# STM32U385xx register map
File version: 1.0
Registers are 32-bit, read-write, reset 0x0 unless marked. A register's access mark holds for its fields unless they carry their own. Offsets are from the block's base; [hi:lo] are bit positions; lines under a group give offsets from that group; {n}, {i} and the like mark numbered series; 'fields as' and 'values as' point back to an identical list.

## TSC — Touch Sensing Controller (TSC)
Base 0x40024000
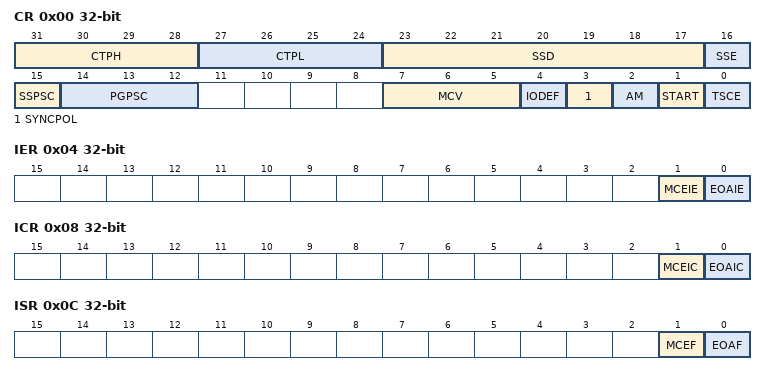
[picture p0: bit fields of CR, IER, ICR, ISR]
0x00 CR — TSC control register
  [31:28] CTPH — CTPH[3:0] bits (Charge Transfer pulse high)
  [27:24] CTPL — CTPL[3:0] bits (Charge Transfer pulse low)
  [23:17] SSD — SSD[6:0] bits (Spread Spectrum Deviation)
  [16] SSE — Spread Spectrum Enable
  [15] SSPSC — Spread Spectrum Prescaler
  [14:12] PGPSC — PGPSC[2:0] bits (Pulse Generator Prescaler)
  [7:5] MCV — MCV[2:0] bits (Max Count Value)
  [4] IODEF — IO default mode
  [3] SYNCPOL — Synchronization pin polarity
  [2] AM — Acquisition mode
  [1] START — Start acquisition
  [0] TSCE — Touch sensing controller enable
0x04 IER — TSC interrupt enable register
  [1] MCEIE — Max count error interrupt enable
  [0] EOAIE — End of acquisition interrupt enable
0x08 ICR — TSC interrupt clear register
  [1] MCEIC — Max count error interrupt clear
  [0] EOAIC — End of acquisition interrupt clear
0x0C ISR — TSC interrupt status register
  [1] MCEF — Max count error flag
  [0] EOAF — End of acquisition flag
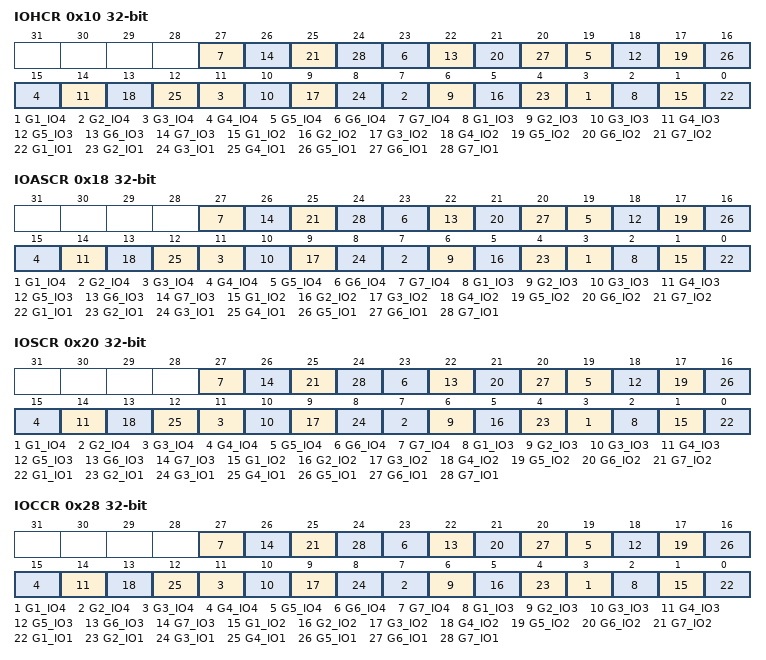
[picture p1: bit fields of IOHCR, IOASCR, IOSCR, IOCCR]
0x10 IOHCR — TSC I/O hysteresis control register
  [4n-1] G{n}_IO4 (n=1..7) — GROUP{n}_IO4 schmitt trigger hysteresis mode
  [4n-2] G{n}_IO3 (n=1..7) — GROUP{n}_IO3 schmitt trigger hysteresis mode
  [4n-3] G{n}_IO2 (n=1..7) — GROUP{n}_IO2 schmitt trigger hysteresis mode
  [4n-4] G{n}_IO1 (n=1..7) — GROUP{n}_IO1 schmitt trigger hysteresis mode
0x18 IOASCR — TSC I/O analog switch control register
  [4n-1] G{n}_IO4 (n=1..7) — GROUP{n}_IO4 analog switch enable
  [4n-2] G{n}_IO3 (n=1..7) — GROUP{n}_IO3 analog switch enable
  [4n-3] G{n}_IO2 (n=1..7) — GROUP{n}_IO2 analog switch enable
  [4n-4] G{n}_IO1 (n=1..7) — GROUP{n}_IO1 analog switch enable
0x20 IOSCR — TSC I/O sampling control register
  [4n-1] G{n}_IO4 (n=1..7) — GROUP{n}_IO4 sampling mode
  [4n-2] G{n}_IO3 (n=1..7) — GROUP{n}_IO3 sampling mode
  [4n-3] G{n}_IO2 (n=1..7) — GROUP{n}_IO2 sampling mode
  [4n-4] G{n}_IO1 (n=1..7) — GROUP{n}_IO1 sampling mode
0x28 IOCCR — TSC I/O channel control register
  [4n-1] G{n}_IO4 (n=1..7) — GROUP{n}_IO4 channel mode
  [4n-2] G{n}_IO3 (n=1..7) — GROUP{n}_IO3 channel mode
  [4n-3] G{n}_IO2 (n=1..7) — GROUP{n}_IO2 channel mode
  [4n-4] G{n}_IO1 (n=1..7) — GROUP{n}_IO1 channel mode
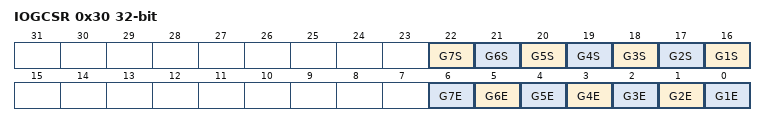
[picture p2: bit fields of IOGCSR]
0x30 IOGCSR — TSC I/O group control status register
  [n+15] G{n}S (n=1..7) — Analog IO GROUP{n} status
  [n-1] G{n}E (n=1..7) — Analog IO GROUP{n} enable
{0x30+4i} IOG{i}CR (i=1..7) — TSC I/O group x counter register, 0x34-0x4C
  [13:0] CNT — CNT[13:0] bits (Counter value)

## RAMCFG
Base 0x40026000
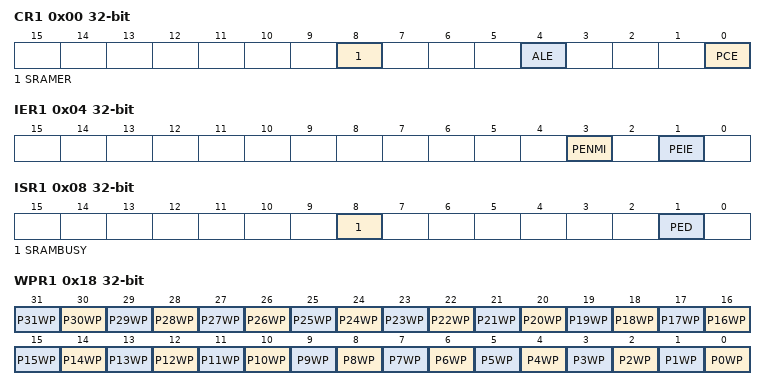
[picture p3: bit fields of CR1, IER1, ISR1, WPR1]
0x00 CR1 — Control Register
  [8] SRAMER — Start Erase
  [4] ALE — Address Latching Enable
  [0] PCE — Parity check Enable
0x04 IER1 — Interrupt enable register
  [3] PENMI — Parity error NMI
  [1] PEIE — Parity error interrupt enable
0x08 ISR1 — Interrupt status register
  [8] SRAMBUSY — SRAM busy with erase operation
  [1] PED — Parity error detected
0x10 PEAR1 — Parity error address register
  [31:0] PEA — Parity error address
0x14 ICR1 — Interrupt clear register
  [1] CPED — Clear parity error detect bit
0x18 WPR1 — Write protection register 1
  [n] P{n}WP (n=0..31) — Write Protection Page {n:02}
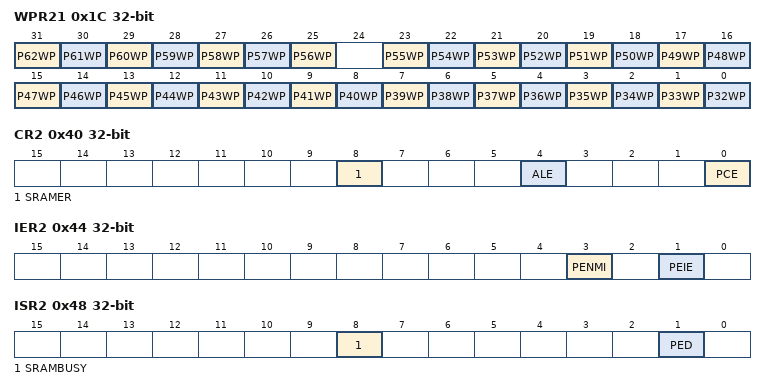
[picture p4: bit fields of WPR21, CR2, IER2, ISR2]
0x1C WPR21 — Write protection register 2
  [n-31] P{n}WP (n=56..62) — Write Protection Page {n}
  [n-32] P{n}WP (n=32..55) — Write Protection Page {n}
0x24 PARKEYR1 — Parity key register
  [7:0] PARKEY — Parity write protection key
0x28 ERKEYR1 — Erase key register
  [7:0] ERASEKEY — Erase write protection key
0x40 CR2 — Control Register
  fields as CR1
0x44 IER2 — Interrupt enable register
  fields as IER1
0x48 ISR2 — Interrupt status register
  fields as ISR1
0x50 PEAR2 — Parity error address register
  [31:0] PEA — Parity error address
0x54 ICR2 — Interrupt clear register
  [1] CPED — Clear parity error detect bit
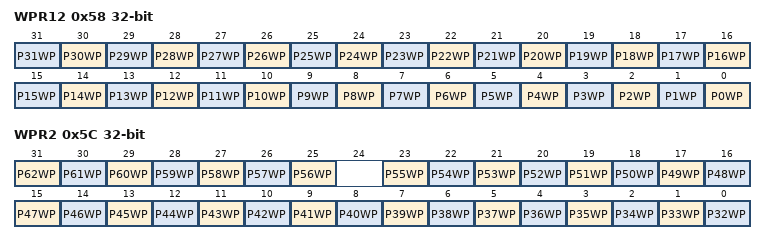
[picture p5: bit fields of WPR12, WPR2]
0x58 WPR12 — Write protection register 1
  [n] P{n}WP (n=0..31) — Write Protection Page {n:02}
0x5C WPR2 — Write protection register 2
  fields as WPR21
0x64 PARKEYR2 — Parity key register
  [7:0] PARKEY — Parity write protection key
0x68 ERKEYR2 — Erase key register
  [7:0] ERASEKEY — Erase write protection key
